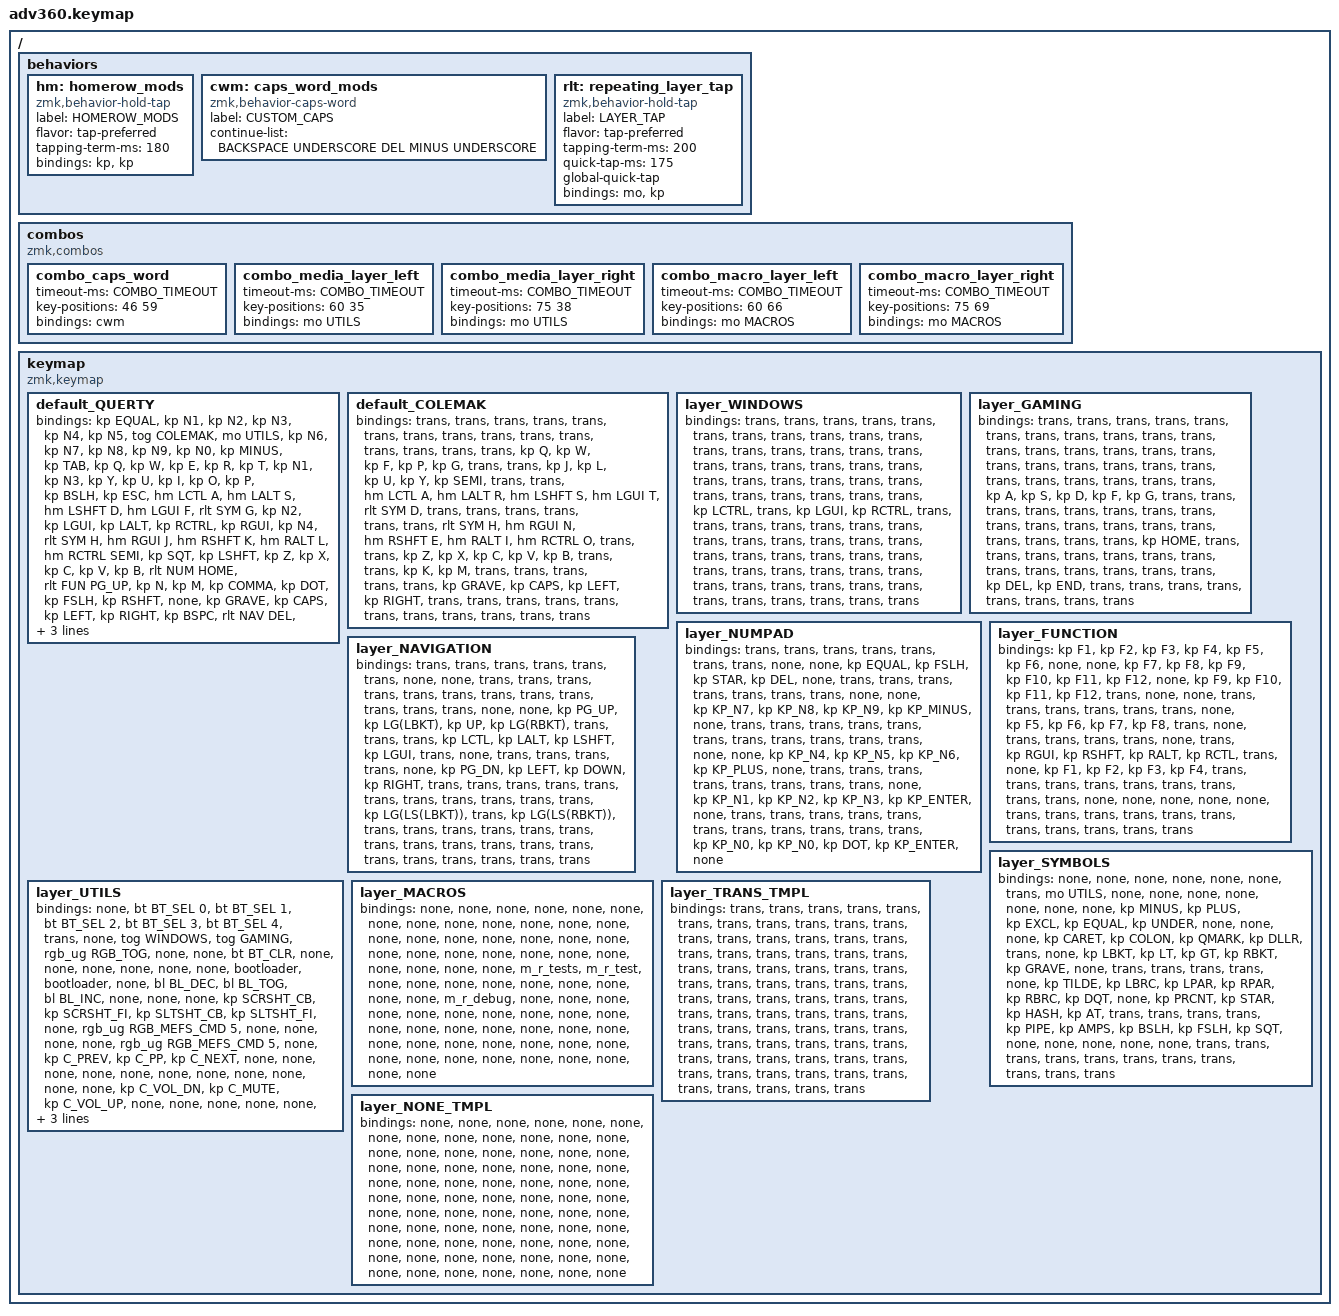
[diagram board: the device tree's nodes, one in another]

/*
 * Copyright (c) 2020 The ZMK Contributors
 *
 * SPDX-License-Identifier: MIT
 */


/* THIS FILE WAS GENERATED!
 *
 * This file was generated automatically. You may or may not want to
 * edit it directly.
 */

/*
00: +  01: 1  02: 2  03: 3  04: 4  05: 5  06:KP                                             07:MO  08: 6  09: 7  10: 8  11: 9  12: 0  13: -
14:TA  15: Q  16: W  17: E  18: R  19: T  20:01                                             21:03  22: Y  23: U  24: I  25: O  26: P  27: \
28:ES  29: A  30: S  31: D  32: F  33: G  34:02         35:LG  36:LA   37:RC  38:RG         39:04  40: H  41: J  42: K  43: L  44: ;  45: '
46:LS  47: Z  48: X  49: C  50: V  51: B                       52:HM   53:PU                       54: N  55: M  56: ,  57: .  58: /  59:RS
60:LF  61: `  62:CA  63:LA  64:RA                65:BS  66:DE  67:EN   68:PD  69:EN  70:SP                71:UA  72:DA  73: [  74: ]  75:RF
 */

#include <behaviors.dtsi>
#include <dt-bindings/zmk/keys.h>
#include <dt-bindings/zmk/bt.h>
#include <dt-bindings/zmk/rgb.h>
#include <dt-bindings/zmk/backlight.h>

#define QUERTY    0
#define COLEMAK   1
#define WINDOWS   2
#define GAMING    3
#define NUM       4
#define FUN       5
#define NAV       6
#define SYM       7
#define UTILS     8
#define MACROS    9

#define HYPER LS(LC(LA(LGUI)))

// Screen Shot to Clip Board
#define SCRSHT_CB LS(LC(LG(N3)))
// Screen Shot to File
#define SCRSHT_FI LS(LG(N3))
// Screen Selection to Clip Board
#define SLTSHT_CB LS(LC(LG(N4)))
// Screen Selection to File
#define SLTSHT_FI LS(LG(N4))
// Lock Screen
#define LOCK_SCR  LC(LG(Q))
#define SLEEP_DIS LS(LC(LA(LG(K))))

#define COMBO_TIMEOUT 300

/ {
  behaviors {
    #include "macros.dtsi"

    hm: homerow_mods {
        compatible = "zmk,behavior-hold-tap";
        label = "HOMEROW_MODS";
        #binding-cells = <2>;
        flavor = "tap-preferred";
        tapping-term-ms = <180>;
        bindings = <&kp>, <&kp>;
    };

    cwm: caps_word_mods {
        compatible = "zmk,behavior-caps-word";
        label = "CUSTOM_CAPS";
        #binding-cells = <0>;
        continue-list = <BACKSPACE UNDERSCORE DEL MINUS UNDERSCORE>;
    };

    rlt: repeating_layer_tap {
        compatible = "zmk,behavior-hold-tap";
        label = "LAYER_TAP";
        #binding-cells = <2>;
        flavor = "tap-preferred";
        tapping-term-ms = <200>;
        quick-tap-ms = <175>;
        global-quick-tap;
        bindings = <&mo>, <&kp>;
    };
  };

    combos {
        compatible = "zmk,combos";
        combo_caps_word {
            timeout-ms = <COMBO_TIMEOUT>;
            key-positions = <46 59>;
            bindings = <&cwm>;
        };
        combo_media_layer_left {
            timeout-ms = <COMBO_TIMEOUT>;
            key-positions = <60 35>;
            bindings = <&mo UTILS>;
        };
        combo_media_layer_right {
            timeout-ms = <COMBO_TIMEOUT>;
            key-positions = <75 38>;
            bindings = <&mo UTILS>;
        };
        combo_macro_layer_left {
            timeout-ms = <COMBO_TIMEOUT>;
            key-positions = <60 66>;
            bindings = <&mo MACROS>;
        };
        combo_macro_layer_right {
            timeout-ms = <COMBO_TIMEOUT>;
            key-positions = <75 69>;
            bindings = <&mo MACROS>;
        };
    };

    keymap {
        compatible = "zmk,keymap";

        default_QUERTY {
            bindings = <
&kp EQUAL  &kp N1      &kp N2      &kp N3       &kp N4      &kp N5      &tog COLEMAK                                                                            &mo UTILS  &kp N6  &kp N7       &kp N8    &kp N9    &kp N0  &kp MINUS
&kp TAB    &kp Q       &kp W       &kp E        &kp R       &kp T       &kp N1                                                                                  &kp N3   &kp Y   &kp U        &kp I     &kp O     &kp P   &kp BSLH
&kp ESC    &hm LCTL A  &hm LALT S  &hm LSHFT D  &hm LGUI F  &rlt SYM G  &kp N2         &kp LGUI     &kp LALT                           &kp RCTRL &kp RGUI       &kp N4   &rlt SYM H    &hm RGUI J      &hm RSHFT K     &hm RALT L  &hm RCTRL SEMI    &kp SQT
&kp LSHFT  &kp Z       &kp X       &kp C        &kp V       &kp B                                   &rlt NUM HOME                      &rlt FUN PG_UP                    &kp N &kp M  &kp COMMA   &kp DOT  &kp FSLH  &kp RSHFT
&none    &kp GRAVE   &kp CAPS    &kp LEFT     &kp RIGHT                    &kp BSPC  &rlt NAV DEL &hm HYPER END    &hm HYPER PG_DN  &kp ENTER &kp SPACE                             &kp UP &kp DOWN  &kp LBKT  &kp RBKT      &none
            >;
        };

        default_COLEMAK {
            bindings = <
&trans &trans     &trans     &trans      &trans     &trans     &trans                                             &trans  &trans  &trans     &trans    &trans    &trans  &trans
&trans &kp Q      &kp W      &kp F       &kp P      &kp G      &trans                                             &trans  &kp J   &kp L      &kp U     &kp Y     &kp SEMI   &trans
&trans &hm LCTL A &hm LALT R &hm LSHFT S &hm LGUI T &rlt SYM D &trans        &trans &trans   &trans &trans        &trans  &rlt SYM H   &hm RGUI N      &hm RSHFT E     &hm RALT I  &hm RCTRL O    &trans
&trans &kp Z      &kp X      &kp C       &kp V      &kp B                              &trans   &trans                       &kp K   &kp M  &trans   &trans  &trans  &trans
&trans &kp GRAVE  &kp CAPS   &kp LEFT    &kp RIGHT                    &trans &trans &trans   &trans &trans &trans                 &trans   &trans  &trans  &trans      &trans
            >;
        };

// Swaps positions for the GUI and Ctrl keys
        layer_WINDOWS {
            bindings = <
&trans  &trans  &trans  &trans &trans  &trans  &trans                                                     &trans &trans &trans &trans &trans &trans &trans
&trans  &trans  &trans  &trans &trans  &trans  &trans                                                     &trans &trans &trans &trans &trans &trans &trans
&trans  &trans  &trans  &trans &trans  &trans  &trans          &kp LCTRL &trans   &kp LGUI &kp RCTRL      &trans &trans &trans &trans &trans &trans &trans
&trans  &trans  &trans  &trans &trans  &trans                          &trans      &trans                        &trans &trans &trans &trans &trans &trans
&trans  &trans  &trans  &trans &trans                  &trans  &trans  &trans      &trans  &trans  &trans               &trans &trans &trans &trans &trans
            >;
        };

// Removes dual-function keys, allowing them to be held down in games.  Generally applied over the WINDOWS layer.
        layer_GAMING {
            bindings = <
&trans  &trans  &trans  &trans &trans  &trans  &trans                                                      &trans &trans &trans &trans &trans &trans &trans
&trans  &trans  &trans  &trans &trans  &trans  &trans                                                      &trans &trans &trans &trans &trans &trans &trans
&trans  &kp A   &kp S   &kp D  &kp F   &kp G   &trans          &trans   &trans      &trans  &trans         &trans &trans &trans &trans &trans &trans &trans
&trans  &trans  &trans  &trans &trans  &trans                           &kp HOME    &trans                        &trans &trans &trans &trans &trans &trans
&trans  &trans  &trans  &trans &trans                  &trans  &kp DEL  &kp END     &trans  &trans  &trans               &trans &trans &trans &trans &trans
            >;
        };

        layer_NUMPAD {
            bindings = <
&trans &trans &trans &trans &trans &trans &trans                                             &none  &none  &kp EQUAL  &kp FSLH    &kp STAR    &kp DEL       &none
&trans &trans &trans &trans &trans &trans &trans                                             &none  &none  &kp KP_N7  &kp KP_N8   &kp KP_N9   &kp KP_MINUS  &none
&trans &trans &trans &trans &trans &trans &trans        &trans &trans   &trans &trans        &none  &none  &kp KP_N4  &kp KP_N5   &kp KP_N6   &kp KP_PLUS   &none
&trans &trans &trans &trans &trans &trans                      &trans   &trans                      &none  &kp KP_N1  &kp KP_N2   &kp KP_N3   &kp KP_ENTER  &none
&trans &trans &trans &trans &trans               &trans &trans &trans   &trans &trans &trans               &kp KP_N0  &kp KP_N0   &kp DOT     &kp KP_ENTER  &none
            >;
        };

        layer_FUNCTION {
            bindings = <
&kp F1  &kp F2  &kp F3   &kp F4   &kp F5   &kp F6  &none                                                   &none  &kp F7  &kp F8  &kp F9  &kp F10  &kp F11  &kp F12
&none   &kp F9  &kp F10  &kp F11  &kp F12  &trans  &none                                                   &none  &trans  &trans  &trans   &trans   &trans   &trans
&none   &kp F5  &kp F6   &kp F7   &kp F8   &trans  &none             &trans  &trans                  &trans  &trans   &none  &trans  &kp RGUI  &kp RSHFT &kp RALT &kp RCTL &trans
&none   &kp F1  &kp F2   &kp F3   &kp F4   &trans                            &trans                  &trans                  &trans  &trans  &trans   &trans   &trans   &trans
&none   &none   &none    &none    &none                    &trans  &trans  &trans                  &trans  &trans  &trans          &trans  &trans   &trans   &trans   &trans
            >;
        };

        layer_NAVIGATION {
            bindings = <
&trans  &trans  &trans  &trans  &trans  &trans            &none                                                  &none &trans     &trans           &trans     &trans           &trans   &trans
&trans  &trans  &trans  &trans  &trans  &trans             &none                                                   &none   &kp PG_UP  &kp LG(LBKT)     &kp UP     &kp LG(RBKT)     &trans   &trans
&trans  &kp LCTL  &kp LALT  &kp LSHFT  &kp LGUI  &trans             &none  &trans  &trans         &trans  &trans   &none   &kp PG_DN  &kp LEFT         &kp DOWN   &kp RIGHT        &trans   &trans
&trans  &trans  &trans  &trans  &trans  &trans                            &trans                  &trans                   &trans     &kp LG(LS(LBKT)) &trans &kp LG(LS(RBKT)) &trans   &trans
&trans  &trans  &trans  &trans  &trans                    &trans  &trans  &trans                  &trans  &trans  &trans              &trans           &trans     &trans           &trans   &trans
            >;
        };

        layer_SYMBOLS {
            bindings = <
&none &none     &none    &none    &none     &none      &trans                                              &mo UTILS &none      &none &none &none &none &none
&none &kp MINUS &kp PLUS &kp EXCL &kp EQUAL &kp UNDER  &none                                               &none   &none      &kp CARET &kp COLON &kp QMARK &kp DLLR &trans
&none &kp LBKT  &kp LT  &kp GT &kp RBKT  &kp GRAVE     &none          &trans  &trans      &trans  &trans   &none   &kp TILDE  &kp LBRC  &kp LPAR  &kp RPAR  &kp RBRC &kp DQT
&none &kp PRCNT  &kp STAR  &kp HASH  &kp AT  &trans                           &trans      &trans                   &trans     &kp PIPE  &kp AMPS  &kp BSLH  &kp FSLH &kp SQT
&none &none &none &none &none                                 &trans  &trans  &trans      &trans  &trans  &trans              &trans    &trans    &trans    &trans    &trans
            >;
        };

        layer_UTILS {
            bindings = <
&none &bt BT_SEL 0  &bt BT_SEL 1  &bt BT_SEL 2  &bt BT_SEL 3   &bt BT_SEL 4 &trans                                                &none                   &tog WINDOWS      &tog GAMING   &rgb_ug RGB_TOG  &none         &none  &bt BT_CLR
&none &none         &none         &none         &none          &none        &bootloader                                           &bootloader             &none             &bl BL_DEC    &bl BL_TOG       &bl BL_INC    &none  &none
&none &kp SCRSHT_CB &kp SCRSHT_FI &kp SLTSHT_CB &kp SLTSHT_FI &none         &rgb_ug RGB_MEFS_CMD 5  &none &none   &none  &none    &rgb_ug RGB_MEFS_CMD 5  &none             &kp C_PREV    &kp C_PP         &kp C_NEXT    &none  &none
&none &none         &none         &none         &none          &none                                      &none   &none                                   &none             &kp C_VOL_DN  &kp C_MUTE       &kp C_VOL_UP  &none  &none
&none &none         &none         &none         &none                                 &none &kp LOCK_SCR  &none   &none  &kp SLEEP_DIS  &none                               &none         &none            &none         &none  &none
            >;
        };

        layer_MACROS {
            bindings = <
&none &none &none &none &none &none &none                                          &none &none &none &none &none &none &none
&none &none &none &none &none &none &none                                          &none &none &none &none &none &none &none
&none &none &none &m_r_tests &m_r_test &none &none        &none &none   &none  &none        &none &none &none &m_r_debug &none &none &none
&none &none &none &none &none &none                    &none   &none                     &none &none &none &none &none &none
&none &none &none &none &none             &none  &none &none   &none  &none  &none              &none &none &none &none &none
            >;
        };

        layer_TRANS_TMPL {
            bindings = <
&trans  &trans  &trans  &trans &trans  &trans  &trans                                                     &trans &trans &trans &trans &trans &trans &trans
&trans  &trans  &trans  &trans &trans  &trans  &trans                                                     &trans &trans &trans &trans &trans &trans &trans
&trans  &trans  &trans  &trans &trans  &trans  &trans          &trans  &trans      &trans  &trans         &trans &trans &trans &trans &trans &trans &trans
&trans  &trans  &trans  &trans &trans  &trans                          &trans      &trans                        &trans &trans &trans &trans &trans &trans
&trans  &trans  &trans  &trans &trans                  &trans  &trans  &trans      &trans  &trans  &trans               &trans &trans &trans &trans &trans
            >;
        };

        layer_NONE_TMPL {
            bindings = <
&none &none &none &none &none &none &none                                          &none &none &none &none &none &none &none
&none &none &none &none &none &none &none                                          &none &none &none &none &none &none &none
&none &none &none &none &none &none &none        &none &none   &none  &none        &none &none &none &none &none &none &none
&none &none &none &none &none &none                    &none   &none                     &none &none &none &none &none &none
&none &none &none &none &none             &none  &none &none   &none  &none  &none              &none &none &none &none &none
            >;
        };

    };
};
